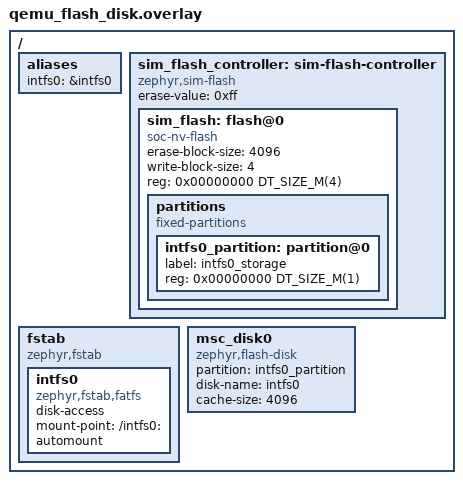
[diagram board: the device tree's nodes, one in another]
/*
 * FAT volume on a flash disk for QEMU targets, mirroring what the native_sim
 * overlay builds on top of that board's own flash controller.
 *
 * The controller deliberately has no unit address or reg: the root node's
 * #address-cells differs between the 32- and 64-bit boards, while the child
 * flash node addresses against the cell counts declared here.
 */

#include <mem.h>

/ {
	aliases {
		intfs0 = &intfs0;
	};

	sim_flash_controller: sim-flash-controller {
		compatible = "zephyr,sim-flash";
		#address-cells = <1>;
		#size-cells = <1>;
		erase-value = <0xff>;

		sim_flash: flash@0 {
			compatible = "soc-nv-flash";
			erase-block-size = <4096>;
			write-block-size = <4>;
			reg = <0x00000000 DT_SIZE_M(4)>;

			partitions {
				compatible = "fixed-partitions";
				#address-cells = <1>;
				#size-cells = <1>;

				intfs0_partition: partition@0 {
					label = "intfs0_storage";
					reg = <0x00000000 DT_SIZE_M(1)>;
				};
			};
		};
	};

	fstab {
		compatible = "zephyr,fstab";

		intfs0: intfs0 {
			compatible = "zephyr,fstab,fatfs";
			disk-access;
			mount-point = "/intfs0:";
			automount;
		};
	};

	msc_disk0 {
		status = "okay";
		compatible = "zephyr,flash-disk";
		partition = <&intfs0_partition>;
		disk-name = "intfs0";
		cache-size = <4096>;
	};
};
